# MCXA133 register map
Vendor: nxp.com; File version: 1.0
CPU: CM33 r2p0, little endian, no MPU, no FPU, VTOR, 3 interrupt priority bits
Registers are 32-bit, read-write, reset 0x0 unless marked. A register's access mark holds for its fields unless they carry their own. Offsets are from the block's base; [hi:lo] are bit positions; {n}, {i} and the like mark numbered series; 'fields as' and 'values as' point back to an identical list.

## I3C0 — I3C
Base 0x40002000
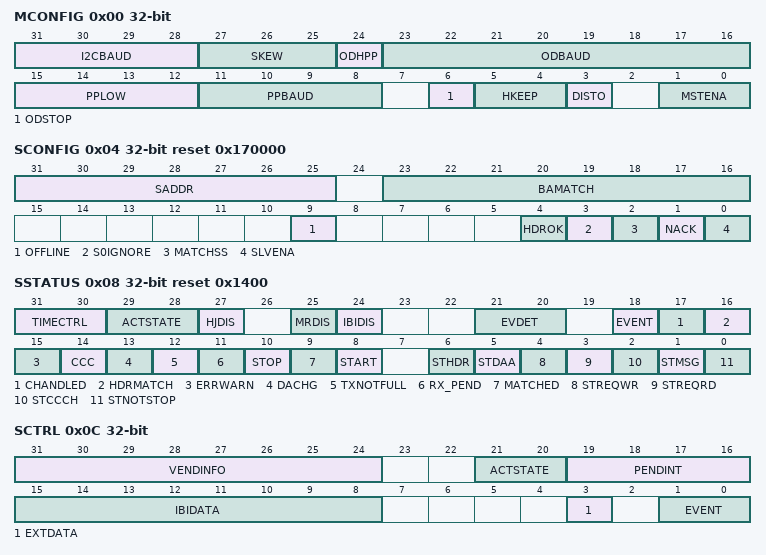
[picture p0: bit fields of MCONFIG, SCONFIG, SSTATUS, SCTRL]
0x00 MCONFIG — Controller Configuration
  [31:28] I2CBAUD — I2C Baud Rate
  [27:25] SKEW
  [24] ODHPP — Open Drain High Push-Pull
    0=DISABLE (ODHPP disabled. Open-Drain SCL High half-clock period is the same as the Open-Drain Low SCL half-period.); 1=ENABLE (ODHPP enabled. Open-Drain High SCL half-lock period is one PPBAUD count for I3C messages. This setting is faster (and works for I3C devices). Any legacy I2C devices on the bus will not see the SCL High at all (less than the spike filter period).)
  [23:16] ODBAUD — Open Drain Baud Rate
  [15:12] PPLOW — Push-Pull Low
  [11:8] PPBAUD — Push-Pull Baud Rate
  [6] ODSTOP — Open Drain Stop
    0=DISABLE (Disable open-drain stop. ODSTOP must be disabled when sending an HDR exit pattern.); 1=ENABLE (Enable open-drain stop. STOP is emitted at open-drain speeds even for I3C messages. In legacy devices, this feature can ensure that the legacy devices see the STOP.)
  [5:4] HKEEP — High-Keeper
    0=NONE; 1=WIRED_IN; 2=PASSIVE_SDA; 3=PASSIVE_ON_SDA_SCL
  [3] DISTO — Disable Timeout
    0=ENABLE (Timeout enabled); 1=DISABLE (Timeout disabled, if timeout is configured)
  [1:0] MSTENA — Controller Enable
    0=MASTER_OFF (CONTROLLER_OFF); 1=MASTER_ON (CONTROLLER_ON); 2=MASTER_CAPABLE (CONTROLLER_CAPABLE); 3=I2C_MASTER_MODE (I2C_CONTROLLER_MODE)
0x04 SCONFIG reset 0x170000 — Target Configuration
  [31:25] SADDR — Static Address
  [23:16] BAMATCH — Bus Available Match
  [9] OFFLINE
    0=DISABLE; 1=ENABLE (Enables wait to ensure the bus is not in HDR mode.)
  [4] HDROK
    0=DISABLE (Disable HDR OK.); 1=ENABLE (Enable HDR OK. Allow HDR-DDR and/or HDR-BT messaging if available by setting the corresponding SIDEXT[BCR] bit to say HDR is available, and the corresponding GETCAPS bit for DDR and/or BT bit permitting use.)
  [3] S0IGNORE — Ignore TE0/TE1 Errors
    0=DISABLE (Do not ignore TE0/TE1 errors); 1=ENABLE (Ignore TE0/TE1 errors. Target does not detect TE0 or TE1 errors, so it does not lock up waiting on an Exit Pattern. This setting should only be used when the bus does not use HDR mode.)
  [2] MATCHSS — Match START or STOP
    0=DISABLE (Match START or STOP disable); 1=ENABLE (Match START or STOP enable. START and STOP sticky SSTATUS bits only become 1 when SSTATUS[MATCHED] is 1. This setting allows START and STOP to be used to detect the end of a message to/from this target.)
  [1] NACK — Not Acknowledge
    0=DISABLE (Always NACK disable); 1=ENABLE (Always NACK enable. The target rejects all requests to it, except for a Common Command Code (CCC) broadcast. NACK = 1 should be used with caution, because the controller may decide that the target is missing, if NACK is overused.)
  [0] SLVENA — Target Enable
    0=DISABLE (Target ignores the I2C or I3C bus); 1=ENABLE (Target can operate on the I2C or I3C bus)
0x08 SSTATUS reset 0x1400 — Target Status
  [31:30] TIMECTRL ro — Time Control
    0=NO_TIME_CONTROL; 1=SYNC (SYNC_MODE); 2=ASYNC_MODE; 3=BOTHSYNCASYNC
  [29:28] ACTSTATE ro — Activity State from Common Command Codes (CCC)
    0=NO_LATENCY; 1=LATENCY_1MS; 2=LATENCY_100MS; 3=LATENCY_10S
  [27] HJDIS ro — Hot-Join Disabled
    0=MR_ENABLED (Hot-Join not disabled); 1=MR_DISABLED (Hot-Join disabled)
  [25] MRDIS ro — Controller Requests Are Disabled
    0=MR_ENABLED (Controller Requests not disabled); 1=MR_DISABLED (Controller Requests disabled)
  [24] IBIDIS ro — In-Band Interrupts Are Disabled
    0=INTERRUPTS_ENABLED (In-Band Interrupts not disabled); 1=INTERRUPTS_DISABLED (In-Band Interrupts disabled)
  [21:20] EVDET ro — Event Details
    0=NONE; 1=NO_REQUEST; 2=NACKED; 3=ACKED
  [18] EVENT write-1-clears
    0=NO_EVENT (No event has occurred.); 1=EVENT (An IBI, CR, or HJ has occurred.)
  [17] CHANDLED write-1-clears — Common Command Code Handled
    0=NOT_HANDLED (CCC handling not in progress.); 1=HANDLED (CCC handling in progress.)
  [16] HDRMATCH write-1-clears — High Data Rate Command Match
    0=NO_MATCH (HDR command did not match.); 1=MATCH (HDR command matched the I3C Dynamic Address of this device.)
  [15] ERRWARN ro — Error Warning
  [14] CCC write-1-clears — Common Command Code
    0=NO_CCC_RECEIVED; 1=CCC_RECEIVED
  [13] DACHG write-1-clears — Dynamic Address Change
    0=NO_CHANGE_DETECTED (No DA change detected.); 1=CHANGE_DETECTED (DA change detected. The target DA has been assigned, re-assigned, or reset (lost) and is now in the state of being valid or none.)
  [12] TXNOTFULL ro — Transmit Buffer Is Not Full
    0=FULL (Transmit buffer full); 1=NOT_FULL (Transmit buffer not full)
  [11] RX_PEND ro — Received Message Pending
    0=NO_MSG_PENDING (No received message is pending.); 1=MSG_PENDING (Received message is pending.)
  [10] STOP write-1-clears
    0=NO_STOP_DETECTED; 1=STOP_DETECTED (Stopped state detected. A STOP state was present on the bus since the bus was last cleared.)
  [9] MATCHED write-1-clears
    0=NOT_MATCHED (No header matched.); 1=MATCHED (An incoming header matched the I3C Dynamic or I2C Static address of this device (if any) since the bus was last cleared.)
  [8] START write-1-clears
    0=START_NOT_DETECTED (No START seen.); 1=START_DETECTED (A START or repeated START was seen after the START bit was last cleared.)
  [6] STHDR ro — Status High Data Rate
    0=NOT_IN_HDR_DDR (I3C bus not in HDR-DDR mode); 1=IN_HDR_DDR (The I3C bus is in HDR-DDR mode, regardless of whether HDR mode is supported by this module or not, and regardless of whether the message is to this module or to some other module.)
  [5] STDAA ro — Status Dynamic Address Assignment
    0=NOT_IN_ENTDAA (Not in ENTDAA mode.); 1=IN_ENTDAA (I3C bus is in Enter Dynamic Address Assignment (ENTDAA) mode, regardless of whether this bus target has a Dynamic Address or not.)
  [4] STREQWR ro — Status Request Write
    0=IDLE (REQ in process is not SDR write data from the controller.); 1=BUSY (REQ in process is SDR write data from the controller to this bus target (or all targets), but not in ENTDAA mode.)
  [3] STREQRD ro — Status Request Read
    0=IDLE (REQ in process is not an SDR read from this target.); 1=BUSY (The REQ in process is an SDR read from this target, or an In-Band Interrupt (IBI) is being pushed out.)
  [2] STCCCH ro — Status Common Command Code Handler
    0=IDLE (No CCC message is being handled.); 1=BUSY (A CCC message is being handled automatically.)
  [1] STMSG ro — Status message
    0=IDLE (Bus target not listening or responding.); 1=BUSY (This bus target is listening to the bus traffic or responding.)
  [0] STNOTSTOP ro — Status Not Stop
    0=STOPPED (I3C module is in a STOP condition.); 1=BUSY (The bus is busy (has activity).)
0x0C SCTRL — Target Control
  [31:24] VENDINFO — Vendor Information
  [21:20] ACTSTATE — Activity State of Target
  [19:16] PENDINT — Pending Interrupt
  [15:8] IBIDATA — In-Band Interrupt Data
  [3] EXTDATA — Extended Data
    0=DISABLE (Extended data disabled.); 1=ENABLE (Extended data enabled. After IBIDATA is emitted, extended data is taken from IBIEXT1 and IBIEXT2 if configured.)
  [1:0] EVENT
    0=NORMAL_MODE; 1=IBI; 2=MASTER_REQUEST (CONTROLLER_REQUEST); 3=HOT_JOIN_REQUEST
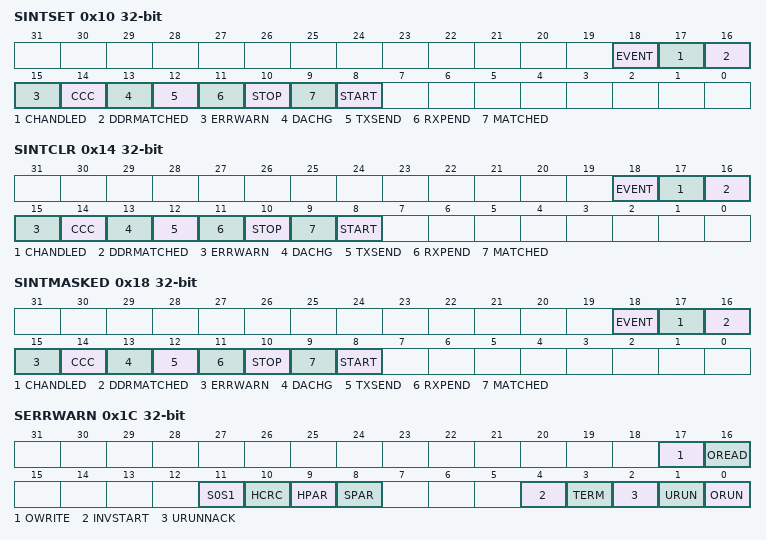
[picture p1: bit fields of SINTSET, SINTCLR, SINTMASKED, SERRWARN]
0x10 SINTSET write-1-sets — Target Interrupt Set
  [18] EVENT write-1-sets — Event Interrupt Enable
    0=DISABLE (Disable Event interrupt); 1=ENABLE (Enable Event interrupt)
  [17] CHANDLED write-1-sets — Common Command Code (CCC) Interrupt Enable
    0=DISABLE (Disable CCC Handled interrupt); 1=ENABLE (Enable CCC Handled interrupt)
  [16] DDRMATCHED write-1-sets — Double Data Rate Interrupt Enable
    0=DISABLE (Disable DDR interrupt); 1=ENABLE (Enable DDR interrupt)
  [15] ERRWARN write-1-sets — Error or Warning Interrupt Enable
    0=DISABLE (Disable error or warning interrupt); 1=ENABLE (Enable error or warning interrupt)
  [14] CCC write-1-sets — Common Command Code (CCC) Interrupt Enable
    0=DISABLE (Disable CCC interrupt); 1=ENABLE (Enable CCC interrupt)
  [13] DACHG write-1-sets — Dynamic Address Change Interrupt Enable
    0=DISABLE (Disable DA Change interrupt); 1=ENABLE (Enable DA Change interrupt)
  [12] TXSEND write-1-sets — Transmit Interrupt Enable
    0=DISABLE (Disable Transmit interrupt); 1=ENABLE (Enable Transmit interrupt)
  [11] RXPEND write-1-sets — Receive Interrupt Enable
    0=DISABLE (Disable Receive interrupt); 1=ENABLE (Enable Receive interrupt)
  [10] STOP write-1-sets — Stop Interrupt Enable
    0=DISABLE (Disable STOP interrupt); 1=ENABLE (Enable STOP interrupt)
  [9] MATCHED write-1-sets — Match Interrupt Enable
    0=DISABLE (Disable match interrupt); 1=ENABLE (Enable match interrupt)
  [8] START write-1-sets — Start Interrupt Enable
    0=DISABLE (Disable START interrupt); 1=ENABLE (Enable START interrupt)
0x14 SINTCLR reset not defined write-1-clears — Target Interrupt Clear
  [18] EVENT write-1-clears — EVENT Interrupt Enable Clear
  [17] CHANDLED write-1-clears — CHANDLED Interrupt Enable Clear
  [16] DDRMATCHED write-1-clears — DDRMATCHED Interrupt Enable Clear
  [15] ERRWARN write-1-clears — ERRWARN Interrupt Enable Clear
  [14] CCC write-1-clears — CCC Interrupt Enable Clear
  [13] DACHG write-1-clears — DACHG Interrupt Enable Clear
  [12] TXSEND write-1-clears — TXSEND Interrupt Enable Clear
  [11] RXPEND write-1-clears — RXPEND Interrupt Enable Clear
  [10] STOP write-1-clears — STOP Interrupt Enable Clear
  [9] MATCHED write-1-clears — MATCHED Interrupt Enable Clear
  [8] START write-1-clears — START Interrupt Enable Clear
0x18 SINTMASKED ro — Target Interrupt Mask
  [18] EVENT — EVENT Interrupt Mask
  [17] CHANDLED — CHANDLED Interrupt Mask
  [16] DDRMATCHED — DDRMATCHED Interrupt Mask
  [15] ERRWARN — ERRWARN Interrupt Mask
  [14] CCC — CCC Interrupt Mask
  [13] DACHG — DACHG Interrupt Mask
  [12] TXSEND — TXSEND Interrupt Mask
  [11] RXPEND — RXPEND Interrupt Mask
  [10] STOP — STOP Interrupt Mask
  [9] MATCHED — MATCHED Interrupt Mask
  [8] START — START interrupt mask
0x1C SERRWARN write-1-clears — Target Errors and Warnings
  [17] OWRITE write-1-clears — Over-write Error
    0=NO_ERROR (No Overwrite error); 1=ERROR (Overwrite error)
  [16] OREAD write-1-clears — Over-read Error
    0=NO_ERROR (No Over-read error); 1=ERROR (Over-read error)
  [11] S0S1 write-1-clears — TE0 or TE1 Error
    0=NO_ERROR (No TE0 or TE1 error); 1=ERROR (TE0 or TE1 error)
  [10] HCRC write-1-clears — HDR-DDR CRC Error
    0=NO_ERROR (No HDR-DDR CRC error); 1=ERROR (HDR-DDR CRC error)
  [9] HPAR write-1-clears — HDR Parity Error
    0=NO_ERROR (No HDR Parity error); 1=ERROR (HDR Parity error)
  [8] SPAR write-1-clears — SDR Parity Error
    0=NO_ERROR (No SDR Parity error); 1=ERROR (SDR Parity error)
  [4] INVSTART write-1-clears — Invalid Start Error
    0=NO_ERROR (No invalid start error); 1=ERROR (Invalid start error)
  [3] TERM write-1-clears — Terminated Error
    0=NO_ERROR (No terminated error); 1=ERROR (Terminated error)
  [2] URUNNACK write-1-clears — Underrun and Not Acknowledged (NACKED) Error
    0=NO_ERROR (No underrun and not acknowledged error); 1=ERROR (Underrun and not acknowledged error)
  [1] URUN write-1-clears — Underrun Error
    0=NO_ERROR (No underrun error); 1=ERROR (Underrun error)
  [0] ORUN write-1-clears — Overrun Error
    0=NO_ERROR (No overrun error); 1=ERROR (Overrun error)
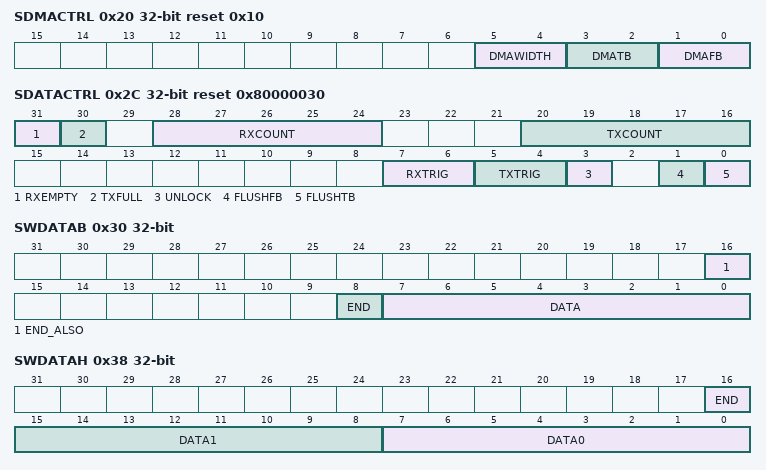
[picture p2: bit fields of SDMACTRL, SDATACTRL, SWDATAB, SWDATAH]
0x20 SDMACTRL reset 0x10 — Target DMA Control
  [5:4] DMAWIDTH — Width of DMA Operations
    0=BYTE_0; 1=BYTE_1; 2=HALF_WORD (Half word (16 bits))
  [3:2] DMATB — DMA Write (To-bus) Trigger
    0=NOT_USED (DMA not used); 1=ENABLE_ONE_FRAME (DMA enabled for one frame (ended by DMA or terminated)); 2=ENABLE (DMA enabled until turned off)
  [1:0] DMAFB — DMA Read (From-bus) Trigger
    0=NOT_USED (DMA not used); 1=ENABLE_ONE_FRAME (DMA is enabled for one frame); 2=ENABLE (DMA enabled until turned off)
0x2C SDATACTRL reset 0x80000030 — Target Data Control
  [31] RXEMPTY ro — Receive Is Empty
    0=RXISNOTEMPTY (Not empty); 1=RXISEMPTY (Empty)
  [30] TXFULL ro — Transmit Is Full
    0=TXISNOTFULL (Not full); 1=TXISFULL (Full)
  [28:24] RXCOUNT ro — Count of Bytes in Receive
  [20:16] TXCOUNT ro — Count of Bytes in Transmit
  [7:6] RXTRIG — Receive Trigger Level
    0=TRIGGRNOTEMPTY (Trigger when not empty); 1=TRIGGRONEFOURTH (Trigger when 1/4 or more full); 2=TRIGGRONEHALF (Trigger when 1/2 or more full); 3=TRIGGRTHREEFOURTHS (Trigger when 3/4 or more full)
  [5:4] TXTRIG — Transmit Trigger Level
    0=TRIGGREMPTY (Trigger when empty); 1=TRIGGRONEFOURTH (Trigger when 1/4 full or less); 2=TRIGGRONEHALF (Trigger when 1/2 full or less); 3=TRIGGRONELESS (Default. Trigger when 1 less than full or less)
  [3] UNLOCK wo
    0=DISABLED (RXTRIG and TXTRIG fields cannot be changed on a write.); 1=ENABLED (RXTRIG and TXTRIG fields can be changed on a write.)
  [1] FLUSHFB wo — Flush the From-bus Buffer or FIFO
  [0] FLUSHTB wo — Flush the To-bus Buffer or FIFO
0x30 SWDATAB wo reset not defined — Target Write Data Byte
  [16] END_ALSO
    0=NOT_END (Not the end. There are more bytes in the message.); 1=END (End. This bit marks the last byte of the message.)
  [8] END
    values as END_ALSO
  [7:0] DATA
0x34 SWDATABE wo reset not defined — Target Write Data Byte End
  [7:0] DATA
0x38 SWDATAH wo reset not defined — Target Write Data Half-word
  [16] END — End of message
    values as SWDATAB.END_ALSO
  [15:8] DATA1
  [7:0] DATA0
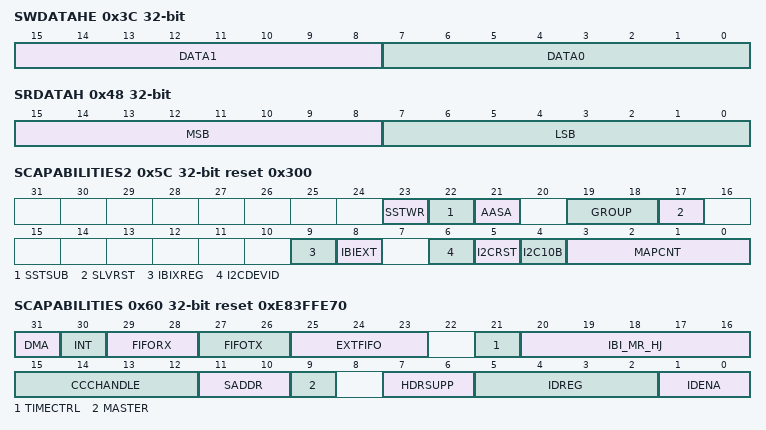
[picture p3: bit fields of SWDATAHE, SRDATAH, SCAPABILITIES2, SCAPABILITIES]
0x3C SWDATAHE wo reset not defined — Target Write Data Half-word End
  [15:8] DATA1, [7:0] DATA0
0x40 SRDATAB ro — Target Read Data Byte
  [7:0] DATA0
0x48 SRDATAH ro — Target Read Data Halfword
  [15:8] MSB — The second byte read from the target
  [7:0] LSB — The first byte read from the target
0x54 SWDATAB1 wo (Byte view) — Target Write Data Byte
  [7:0] DATA
0x54 SWDATAH1 wo (Halfword view) — Target Write Data Halfword
  [15:0] DATA
0x5C SCAPABILITIES2 ro reset 0x300 — Target Capabilities 2
  [23] SSTWR — Target-Target(s)-Tunnel Write Capable
    0=NOTSUPPORTED (Not write capable); 1=SUPPORTED (Write capable)
  [22] SSTSUB — Target-Target(s)-Tunnel Subscriber Capable
    0=NOTSUPPORTED (Not subscriber capable); 1=SUPPORTED (Subscriber capable)
  [21] AASA — Supports SETAASA
    0=NOTSUPPORTED (Does not support SETAASA); 1=SUPPORTED (Supports SETAASA)
  [19:18] GROUP
    0=NOTSUPPORTED (Does not supports v1.1 Group addressing); 1=ONE (Supports one group); 2=TWO (Supports two groups); 3=THREE (Supports three groups)
  [17] SLVRST — Target Reset
    0=DISABLE (Does not support Target Reset); 1=ENABLE (Supports Target Reset)
  [9] IBIXREG — In-Band Interrupt Extended Register
    0=DISABLE (Does not support extended registers for IBIs); 1=ENABLE (Supports extended registers for IBIs)
  [8] IBIEXT — In-Band Interrupt EXTDATA
    0=DISABLE (Does not support IBIEXT); 1=ENABLE (Supports IBIEXT)
  [6] I2CDEVID — I2C Device ID
    0=DISABLE (Does not support I2C device ID); 1=ENABLE (Supports I2C device ID)
  [5] I2CRST — I2C Software Reset
    0=DISABLE (Does not support I2C software reset); 1=ENABLE (Supports I2C software reset)
  [4] I2C10B — I2C 10-bit Address
    0=DISABLE (Does not support 10-bit I2C address); 1=ENABLE (Supports 10-bit I2C address)
  [3:0] MAPCNT — Map Count
0x60 SCAPABILITIES ro reset 0xE83FFE70 — Target Capabilities
  [31] DMA — Direct Memory Access
    0=DMANO (Not supported); 1=DMAYES (Supported)
  [30] INT — Interrupts
    0=INTERRUPTSNO (Not supported); 1=INTERRUPTSYES (Supported)
  [29:28] FIFORX — FIFO Receive
    0=FIFO_2BYTE (Two or three); 1=FIFO_4BYTE (Four); 2=FIFO_8BYTE (Eight); 3=FIFO_16BYTE (16 or larger)
  [27:26] FIFOTX — FIFO Transmit
    0=FIFO_2BYTE (Two); 1=FIFO_4BYTE (Four); 2=FIFO_8BYTE (Eight); 3=FIFO_16BYTE (16 or larger)
  [25:23] EXTFIFO — External FIFO
    0=NO_EXT_FIFO (No external FIFO is available); 1=STD_EXT_FIFO (Standard available or free external FIFO); 2=REQUEST_EXT_FIFO (Request track external FIFO)
  [21] TIMECTRL — Time Control
    0=NO_TIME_CONTROL_TYPE (No time control enabled); 1=ATLEAST1_TIME_CONTROL (At least one time-control type supported)
  [20:16] IBI_MR_HJ — In-Band Interrupts, Controller Requests, Hot-Join Events
    0=ALL_DISABLED (Application cannot generate IBI, CR, or HJ.); 0bxxxx1=IBI (Application can generate an IBI.); 0bxxx1x=IBI_HAS_DATA (When bit 0 = 1, the IBI has data from the SCTRL register.); 0bxx1xx=MASTER_REQUEST (Application can generate a Controller Request for a secondary controller.); 0bx1xxx=HOT_JOIN (Application can generate a Hot-Join event.); 0b1xxxx=BAMATCH_FOR_BUS (Application can use SCONFIG[BAMATCH] for bus-available timing.)
  [15:12] CCCHANDLE — Common Command Codes Handling
    0=ALL_DISABLED (All handling features below are disabled.); 0bxxx1=BLOCK_HANDLE (The block (I3C module) manages events, activities, status, HDR, and if enabled for it, ID and static-address-related items.); 0bxx1x=MAX_READ_WRITE (The block manages maximum read and write lengths, and max data speed.); 0bx1xx=PENDINT_ACTSTATE (GETSTATUS CCC returns SCTRL[PENDINT] and SCTRL[ACTSTATE] values.); 0b1xxx=VENDINFO (GETSTATUS CCC returns SCTRL[VENDINFO] value.)
  [11:10] SADDR — Static Address
    0=NO_STATIC (No static address); 1=STATIC (Static address is fixed in hardware); 2=HW_CONTROL (Hardware controls the static address dynamically (for example, from the pin strap)); 3=CONFIG (SCONFIG register supplies the static address)
  [9] MASTER — Controller
    0=MASTERNOTSUPPORTED (Not supported); 1=MASTERSUPPORTED (Supported)
  [7:6] HDRSUPP — High Data Rate Support
    0=NO_HDR (No HDR modes supported); 1=DDR (Double Data Rate mode supported)
  [5:2] IDREG — ID Register
    0=ALL_DISABLED (All ID register features below are disabled.); 0bxxx1=ID_INSTANCE (ID Instance is a register, and is used if there is no PARTNO register.); 0bxx1x=IDRAND (An ID Random field is available.); 0bx1xx=DCR (A Device Characteristic Register (DCR) is available.); 0b1xxx=BCR (A Bus Characteristics Register (BCR) is available.)
  [1:0] IDENA — ID 48b Handler
    0=APPLICATION; 1=HW (Hardware); 2=HW_BUT (Hardware, but the I3C module instance handles ID 48b); 3=PARTNO (A part number register (PARTNO))
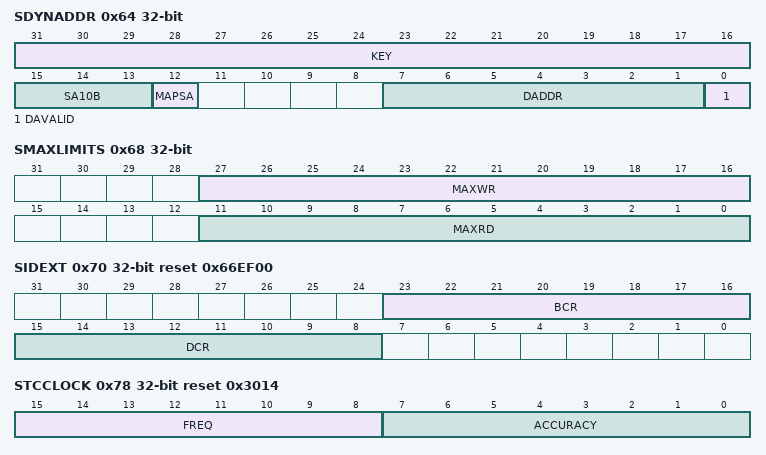
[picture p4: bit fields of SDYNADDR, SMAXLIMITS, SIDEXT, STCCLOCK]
0x64 SDYNADDR — Target Dynamic Address
  [31:16] KEY
  [15:13] SA10B wo — 10bit Static Address
  [12] MAPSA wo — Map a Static Address
  [7:1] DADDR — Dynamic Address
  [0] DAVALID — Dynamic Address Valid
    0=DANOTASSIGNED (DANOTASSIGNED: a Dynamic Address is not assigned); 1=DAASSIGNED (DAASSIGNED: a Dynamic Address is assigned)
0x68 SMAXLIMITS — Target Maximum Limits
  [27:16] MAXWR — Maximum Write Length
  [11:0] MAXRD — Maximum Read Length
0x6C SIDPARTNO reset 0x30000000 — Target ID Part Number
  [31:0] PARTNO — Part number
0x70 SIDEXT reset 0x66EF00 — Target ID Extension
  [23:16] BCR — Bus Characteristics Register
  [15:8] DCR — Device Characteristic Register
0x74 SVENDORID reset 0x11B — Target Vendor ID
  [14:0] VID — Vendor ID
0x78 STCCLOCK reset 0x3014 — Target Time Control Clock
  [15:8] FREQ — Clock Frequency
  [7:0] ACCURACY — Clock Accuracy
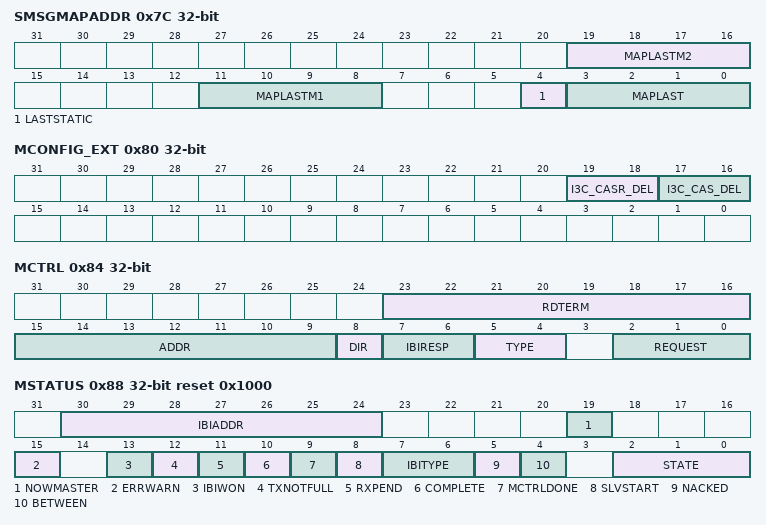
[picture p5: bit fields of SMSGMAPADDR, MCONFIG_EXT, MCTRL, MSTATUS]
0x7C SMSGMAPADDR ro — Target Message Map Address
  [19:16] MAPLASTM2 — Matched Previous Index 2
  [11:8] MAPLASTM1 — Matched Previous Address Index 1
  [4] LASTSTATIC — Last Static Address Matched
    0=I3C (I3C dynamic address); 1=I2C (I2C static address)
  [3:0] MAPLAST — Matched Address Index
0x80 MCONFIG_EXT — Controller Extended Configuration
  [19:18] I3C_CASR_DEL — I3C CAS Delay After Repeated START
    0=NO_DELAY; 1=ONE_HALF_CLK (Increases SCL clock period by 1/2.); 2=ONE_CLK (Increases SCL clock period by 1.); 3=ONE_AND_ONE_HALF_CLK (Increases SCL clock period by 1 1/2.)
  [17:16] I3C_CAS_DEL — I3C CAS Delay after START
    values as I3C_CASR_DEL
0x84 MCTRL — Controller Control
  [23:16] RDTERM — Read Terminate Counter
  [15:9] ADDR — Address
  [8] DIR — Direction
    0=DIRWRITE (Write); 1=DIRREAD (Read)
  [7:6] IBIRESP — In-Band Interrupt Response
    0=ACK (ACK (acknowledge)); 1=NACK (NACK (reject)); 2=ACK_WITH_MANDATORY (Acknowledge with mandatory byte); 3=MANUAL
  [5:4] TYPE — Bus Type with EmitStartAddr
    0=I3C; 1=I2C; 2=DDR
  [2:0] REQUEST
    0=NONE; 1=EMITSTARTADDR; 2=EMITSTOP; 3=IBIACKNACK; 4=PROCESSDAA; 6=FORCEEXIT (Force Exit and Target Reset); 7=AUTOIBI
0x88 MSTATUS reset 0x1000 — Controller Status
  [30:24] IBIADDR ro — IBI Address
  [19] NOWMASTER write-1-clears — Module Is Now Controller
    0=NOT_MASTER (Module has not become controller); 1=MASTER (Module has become controller)
  [15] ERRWARN ro — Error Or Warning
    0=NO_ERROR (No error or warning); 1=ERROR (Error or warning)
  [13] IBIWON write-1-clears — In-Band Interrupt (IBI) Won
    0=NOT_WON (No IBI arbitration won); 1=WON (IBI arbitration won)
  [12] TXNOTFULL ro — TX Buffer or FIFO Not Full
    0=FULL (Receive buffer or FIFO full); 1=NOTFULL (Receive buffer or FIFO not full)
  [11] RXPEND ro
    0=IDLE (No receive message pending); 1=PENDING (Receive message pending)
  [10] COMPLETE write-1-clears
    0=NOT_COMPLETE; 1=COMPLETE
  [9] MCTRLDONE write-1-clears — Controller Control Done
    0=NOT_DONE; 1=DONE
  [8] SLVSTART write-1-clears — Target Start
    0=NOT_START (Target not requesting START); 1=START (Target requesting START)
  [7:6] IBITYPE ro — In-Band Interrupt (IBI) Type
    0=NONE; 1=IBI (In-Band Interrupt); 2=MR (Controller Request); 3=HJ (Hot-Join)
  [5] NACKED ro — Not Acknowledged
    0=NOT_NACKED; 1=NACKED (NACKed (not acknowledged))
  [4] BETWEEN ro
    0=INACTIVE; 1=ACTIVE
  [2:0] STATE ro — State Of The Controller
    0=IDLE; 1=SLVREQ; 2=MSGSDR; 3=NORMACT; 4=DDR (MSGDDR); 5=DAA; 6=IBIACK; 7=IBIRCV
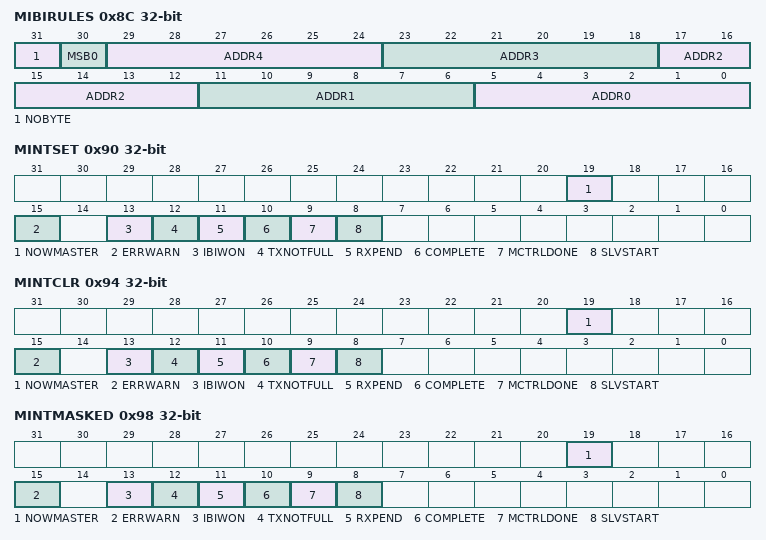
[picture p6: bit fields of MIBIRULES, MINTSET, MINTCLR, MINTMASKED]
0x8C MIBIRULES — Controller In-band Interrupt Registry and Rules
  [31] NOBYTE — No IBI byte
    0=IBIBYTE (With mandatory IBI byte); 1=NO_IBIBYTE (Without mandatory IBI byte)
  [30] MSB0 — Most Significant Address Bit Is 0
    0=DISABLE (MSB is not 0.); 1=ENABLE (For all I3C dynamic addresses, MSB is 0.)
  [6n+5:6n] ADDR{n} (n=0..4)
0x90 MINTSET write-1-sets — Controller Interrupt Set
  [19] NOWMASTER write-1-sets — Now Controller (now this I3C module is a controller) Interrupt Enable
    0=DISABLE; 1=ENABLE
  [15] ERRWARN write-1-sets — Error or Warning (ERRWARN) Interrupt Enable
    0=DISABLE; 1=ENABLE
  [13] IBIWON write-1-sets — In-Band Interrupt (IBI) Won Interrupt Enable
    0=DISABLE; 1=ENABLE
  [12] TXNOTFULL write-1-sets — Transmit Buffer/FIFO is not full interrupt enable
    0=DISABLE; 1=ENABLE
  [11] RXPEND write-1-sets — Receive Pending Interrupt Enable
  [10] COMPLETE write-1-sets — Completed Message Interrupt Enable
    0=DISABLE; 1=ENABLE
  [9] MCTRLDONE write-1-sets — Controller Control Done Interrupt Enable
    0=DISABLE; 1=ENABLE
  [8] SLVSTART write-1-sets — Target Start Interrupt Enable
    0=DISABLE; 1=ENABLE
0x94 MINTCLR reset not defined write-1-clears — Controller Interrupt Clear
  [all] fields
    0=NONE (No effect); 1=CLEAR (Corresponding interrupt enable becomes 0)
  [19] NOWMASTER write-1-clears — NOWCONTROLLER Interrupt Enable Clear
  [15] ERRWARN write-1-clears — ERRWARN Interrupt Enable Clear
  [13] IBIWON write-1-clears — IBIWON Interrupt Enable Clear
  [12] TXNOTFULL write-1-clears — TXNOTFULL Interrupt Enable Clear
  [11] RXPEND write-1-clears — RXPEND Interrupt Enable Clear
  [10] COMPLETE write-1-clears — COMPLETE Interrupt Enable Clear
  [9] MCTRLDONE write-1-clears — MCTRLDONE Interrupt Enable Clear
  [8] SLVSTART write-1-clears — SLVSTART Interrupt Enable Clear
0x98 MINTMASKED ro — Controller Interrupt Mask
  [19] NOWMASTER — NOWCONTROLLER Interrupt Mask
    0=NOT_ENABLED (Interrupt not enabled and/or not active); 1=ENABLED (Interrupt enabled and active)
  [15] ERRWARN — ERRWARN Interrupt Mask
    values as NOWMASTER
  [13] IBIWON — IBIWON Interrupt Mask
    values as NOWMASTER
  [12] TXNOTFULL — TXNOTFULL Interrupt Mask
    values as NOWMASTER
  [11] RXPEND — RXPEND Interrupt Mask
  [10] COMPLETE — COMPLETE Interrupt Mask
    values as NOWMASTER
  [9] MCTRLDONE — MCTRLDONE Interrupt Mask
    values as NOWMASTER
  [8] SLVSTART — SLVSTART Interrupt Mask
    values as NOWMASTER
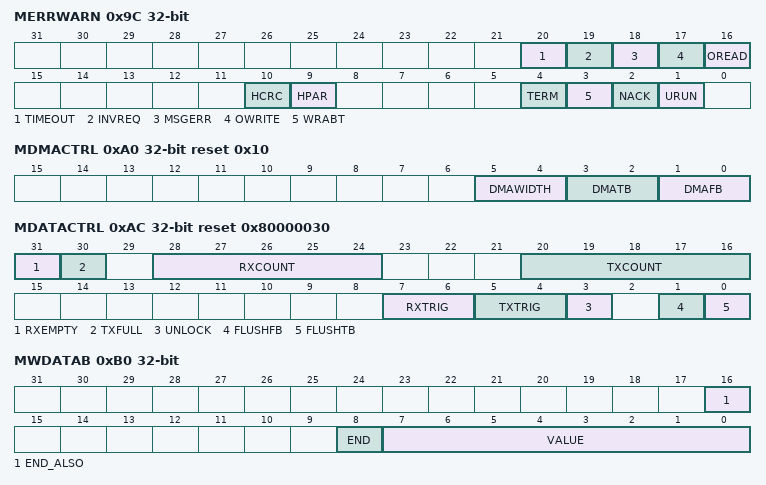
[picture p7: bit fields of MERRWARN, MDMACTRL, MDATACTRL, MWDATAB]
0x9C MERRWARN write-1-clears — Controller Errors and Warnings
  [all] fields
    0=NO_ERROR; 1=ERROR
  [20] TIMEOUT write-1-clears — Timeout Error
  [19] INVREQ write-1-clears — Invalid Request Error
  [18] MSGERR write-1-clears — Message Error
  [17] OWRITE write-1-clears — Over-write Error
  [16] OREAD write-1-clears — Over-read Error
  [10] HCRC write-1-clears — High Data Rate CRC Error
  [9] HPAR write-1-clears — High Data Rate Parity
  [4] TERM write-1-clears — Terminate Error
  [3] WRABT write-1-clears — Write Abort Error
  [2] NACK write-1-clears — Not Acknowledge Error
  [1] URUN write-1-clears — Underrun error
0xA0 MDMACTRL reset 0x10 — Controller DMA Control
  [5:4] DMAWIDTH
    0=BYTE_0; 1=BYTE_1; 2=HALF_WORD (Halfword (16 bits))
  [3:2] DMATB — DMA To Bus
    0=NOT_USED (DMA is not used); 1=ENABLE_ONE_FRAME (Enable DMA for one frame (ended by DMA or Terminated)); 2=ENABLE (Enable DMA until DMA is turned off)
  [1:0] DMAFB — DMA From Bus
    0=NOT_USED (DMA is not used); 1=ENABLE_ONE_FRAME (Enable DMA for one frame); 2=ENABLE (Enable DMA until DMA is turned off)
0xAC MDATACTRL reset 0x80000030 — Controller Data Control
  [31] RXEMPTY ro — Receive Is Empty
    0=NOT_EMPTY (Receive FIFO or buffer is not yet empty.); 1=EMPTY (Receive FIFO or buffer is empty.)
  [30] TXFULL ro — Transmit Is Full
    0=NOT_FULL (Transmit FIFO or buffer is not yet full.); 1=FULL (Transmit FIFO or buffer is full.)
  [28:24] RXCOUNT ro — Receive Byte Count
  [20:16] TXCOUNT ro — Transmit Byte Count
  [7:6] RXTRIG — Receive Trigger Level
    0=NOT_EMPTY (Trigger when not empty); 1=QUARTER_OR_MORE (Trigger when 1/4 full or more); 2=HALF_OR_MORE (Trigger when 1/2 full or more); 3=THREE_QUARTER_OR_MORE (Trigger when 3/4 full or more)
  [5:4] TXTRIG — Transmit Trigger Level
    0=EMPTY (Trigger when empty); 1=QUARTER_OR_LESS (Trigger when 1/4 full or less); 2=HALF_OR_LESS (Trigger when 1/2 full or less); 3=FULL_OR_LESS (Default. Trigger when 1 less than full or less)
  [3] UNLOCK wo
    0=DISABLED (Locked. RXTRIG and TXTRIG fields cannot be changed on a write.); 1=ENABLED (Unlocked. RXTRIG and TXTRIG fields can be changed on a write.)
  [1] FLUSHFB wo — Flush From-bus Buffer or FIFO
    0=NO_ACTION; 1=FLUSH (Flush the buffer)
  [0] FLUSHTB wo — Flush To-bus Buffer or FIFO
    0=NO_ACTION; 1=FLUSH (Flush the buffer)
0xB0 MWDATAB wo reset not defined — Controller Write Data Byte
  [16] END_ALSO — End of Message Also
    0=NOT_END (Not the end. More bytes are assumed to be in the message.); 1=END (End. The END bit marks the last byte of the message.)
  [8] END — End of Message
    values as END_ALSO
  [7:0] VALUE — Data Byte
0xB4 MWDATABE wo reset not defined — Controller Write Data Byte End
  [7:0] VALUE — Data
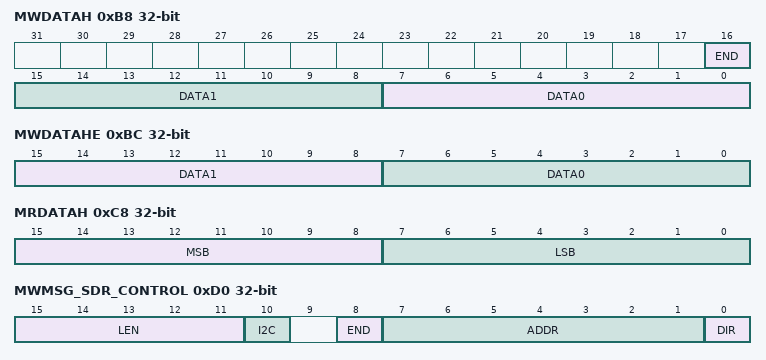
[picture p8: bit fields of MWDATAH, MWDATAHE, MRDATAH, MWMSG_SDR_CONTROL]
0xB8 MWDATAH wo reset not defined — Controller Write Data Halfword
  [16] END — End of message
    values as MWDATAB.END_ALSO
  [15:8] DATA1 — Data Byte 1
  [7:0] DATA0 — Data Byte 0
0xBC MWDATAHE wo reset not defined — Controller Write Data Halfword End
  [15:8] DATA1 — Data Byte 1
  [7:0] DATA0 — Data Byte 0
0xC0 MRDATAB ro — Controller Read Data Byte
  [7:0] VALUE
0xC8 MRDATAH ro — Controller Read Data Halfword
  [15:8] MSB, [7:0] LSB
0xCC MWDATAB1 wo (BYTE view) — Controller Write Byte Data 1(to bus)
  [7:0] VALUE
0xCC MWDATAH1 wo (HALFWORD view) — Controller Write Halfword Data (to bus)
  [15:0] VALUE
0xD0 MWMSG_SDR_CONTROL wo reset not defined (CONTROL view) — Controller Write Message Control in SDR mode
  [15:11] LEN — Length
  [10] I2C
    0=I3CMESSAGE; 1=I2CMESSAGE
  [8] END — End of SDR Message
    0=NOT_END (Not the end. SDR message ends waiting for a new SDR message (issues a repeated START for a new message).); 1=END (End. SDR message ends at the STOP.)
  [7:1] ADDR — Address
  [0] DIR — Direction
    0=WRITE; 1=READ
0xD0 MWMSG_SDR_DATA wo (DATA view) — Controller Write Message Data in SDR mode
  [15:0] DATA16B — Data
0xD4 MRMSG_SDR ro — Controller Read Message in SDR mode
  [15:0] DATA
0xD8 MWMSG_DDR_CONTROL wo reset not defined (CONTROL view) — Controller Write Message in DDR mode: First Control Word
  [15:0] ADDRCMD — Address Command
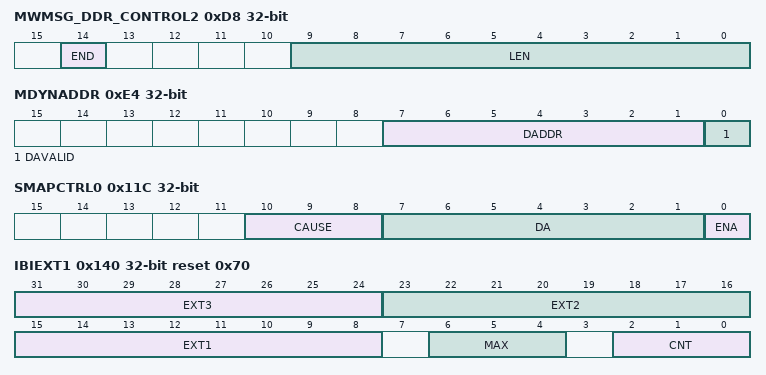
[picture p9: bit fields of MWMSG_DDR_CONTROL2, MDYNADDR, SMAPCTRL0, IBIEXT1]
0xD8 MWMSG_DDR_CONTROL2 wo reset not defined (CONTROL2 view) — Controller Write Message in DDR mode Control 2
  [14] END — End of message
    0=NOT_END (Not the end. DDR message ends waiting for a new DDR message (will issue a HDR Restart for the new message).); 1=END (End. DDR message ends on HDR Exit.)
  [9:0] LEN — Length of Message
0xD8 MWMSG_DDR_DATA wo (DATA view) — Controller Write Message Data in DDR mode
  [15:0] DATA16B — Data
0xDC MRMSG_DDR ro — Controller Read Message in DDR mode
  [15:0] DATA
0xE4 MDYNADDR — Controller Dynamic Address
  [7:1] DADDR — Dynamic address
  [0] DAVALID — Dynamic address valid
    0=NO_VALID (No valid DA assigned); 1=VALID (Valid DA assigned)
0x11C SMAPCTRL0 ro — Map Feature Control 0
  [10:8] CAUSE
    0=NONE (No information. This value occurs when not configured to write DA.); 1=ENTDAA (Set using ENTDAA); 2=SETDASA (Set using SETDASA, SETAASA, or SETNEWDA); 3=RSTDAA (Cleared using RSTDAA); 4=AUTOMAP (Auto MAP change happened last. The change may have changed this DA as well (for example, ENTDAA, and SETAASA), but at least one MAP entry automatically changed after.)
  [7:1] DA — Dynamic Address
  [0] ENA — Enable Primary Dynamic Address
    0=DISABLE; 1=ENABLE
0x140 IBIEXT1 reset 0x70 — Extended IBI Data 1
  [31:24] EXT3 — Extra byte 3
  [23:16] EXT2 — Extra byte 2
  [15:8] EXT1 — Extra byte 1
  [6:4] MAX ro — Maximum
  [2:0] CNT — Count
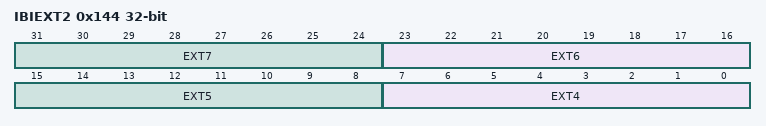
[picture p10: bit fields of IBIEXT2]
0x144 IBIEXT2 — Extended IBI Data 2
  [8n-25:8n-32] EXT{n} (n=4..7) — Extra byte {n}
0xFFC SID ro reset 0xEDCB0100 — Target Module ID
  [31:0] ID

## Notices in the file
Copyright 2016-2026 NXP
SPDX-License-Identifier: BSD-3-Clause
